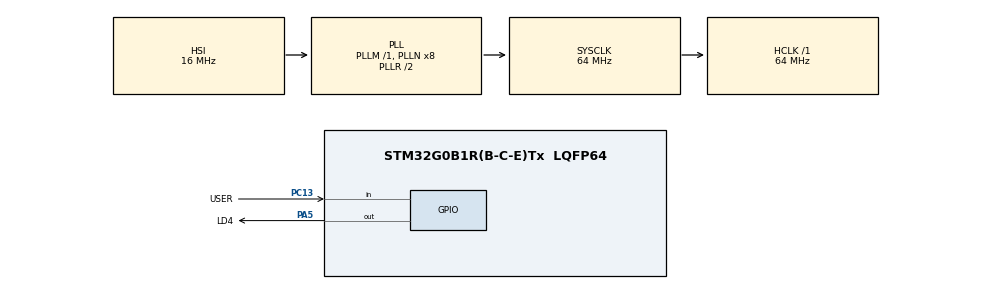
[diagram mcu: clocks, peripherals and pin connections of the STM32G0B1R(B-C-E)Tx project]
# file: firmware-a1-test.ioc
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Mcu.Family=STM32G0
Mcu.Name=STM32G0B1R(B-C-E)Tx
Mcu.Package=LQFP64
PA13.Mode=Serial_Wire
PA13.Signal=SYS_SWDIO
PA14-BOOT0.Mode=Serial_Wire
PA14-BOOT0.Signal=SYS_SWCLK
PA5.GPIO_Label=LD4
PA5.Signal=GPIO_Output
PC13.GPIO_Label=USER
PC13.Signal=GPIO_Input
ProjectManager.HeapSize=0x200
ProjectManager.StackSize=0x400
ProjectManager.TargetToolchain=STM32CubeIDE
RCC.ADCFreq_Value=64000000
RCC.AHBFreq_Value=64000000
RCC.CortexFreq_Value=64000000
RCC.EXTERNAL_CLOCK_VALUE=48000
RCC.HCLKFreq_Value=64000000
RCC.HSE_VALUE=8000000
RCC.HSI48_VALUE=48000000
RCC.HSI_VALUE=16000000
RCC.LSE_VALUE=32768
RCC.SYSCLKFreq_VALUE=64000000
RCC.SYSCLKSource=RCC_SYSCLKSOURCE_PLLCLK
RCC.USBFreq_Value=48000000
RCC.VCOOutputFreq_Value=128000000
VP_SYS_VS_DBSignals.Mode=DisableDeadBatterySignals
board=custom

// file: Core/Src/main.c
/* USER CODE BEGIN Header */
/**
  ******************************************************************************
  * @file           : main.c
  * @brief          : Main program body
  ******************************************************************************
  * @attention
  *
  * Copyright (c) 2022 STMicroelectronics.
  * All rights reserved.
  *
  * This software is licensed under terms that can be found in the LICENSE file
  * in the root directory of this software component.
  * If no LICENSE file comes with this software, it is provided AS-IS.
  *
  ******************************************************************************
  */
/* USER CODE END Header */
#include "main.h"
#include "gpio.h"

/* USER CODE BEGIN PV */
uint32_t i;
/* USER CODE END PV */

void SystemClock_Config(void);

/* USER CODE BEGIN 0 */

/**
 * @brief		Sum a and b
 */
uint8_t sum8(uint8_t a, uint8_t b){
	uint8_t c;

	c = a+b;

	return c;
}

/**
 * @brief		Sum a and b
 */
uint_fast8_t sum8_fast(uint_fast8_t a, uint_fast8_t b){
	uint_fast8_t c;

	c = a+b;

	return c;
}

/* USER CODE END 0 */

int main(void)
{
  /* USER CODE BEGIN 1 */
	uint8_t A = 3, B = 19, C;
	uint_fast8_t Af = 3, Bf = 19, Cf;
  /* USER CODE END 1 */

  /* MCU Configuration--------------------------------------------------------*/

  /* Reset of all peripherals, Initializes the Flash interface and the Systick. */
  HAL_Init();

  /* Configure the system clock */
  SystemClock_Config();

  /* Initialize all configured peripherals */
  MX_GPIO_Init();

  /* Infinite loop */
  /* USER CODE BEGIN WHILE */
  i = 0;
  while (1)
  {
	  if (HAL_GPIO_ReadPin(USER_GPIO_Port, USER_Pin) == GPIO_PIN_RESET){
		  HAL_GPIO_WritePin(LD4_GPIO_Port, LD4_Pin, GPIO_PIN_SET);
	  }
	  else{
		  HAL_GPIO_WritePin(LD4_GPIO_Port, LD4_Pin, GPIO_PIN_RESET);
	  }

	  C = sum8(A, B);
	  Cf = sum8_fast(Af, Bf);

	  i++;
    /* USER CODE END WHILE */

  }
}

void SystemClock_Config(void)
{
  RCC_OscInitTypeDef RCC_OscInitStruct = {0};
  RCC_ClkInitTypeDef RCC_ClkInitStruct = {0};

  /** Configure the main internal regulator output voltage
  */
  HAL_PWREx_ControlVoltageScaling(PWR_REGULATOR_VOLTAGE_SCALE1);
  /** Initializes the RCC Oscillators according to the specified parameters
  * in the RCC_OscInitTypeDef structure.
  */
  RCC_OscInitStruct.OscillatorType = RCC_OSCILLATORTYPE_HSI;
  RCC_OscInitStruct.HSIState = RCC_HSI_ON;
  RCC_OscInitStruct.HSIDiv = RCC_HSI_DIV1;
  RCC_OscInitStruct.HSICalibrationValue = RCC_HSICALIBRATION_DEFAULT;
  RCC_OscInitStruct.PLL.PLLState = RCC_PLL_ON;
  RCC_OscInitStruct.PLL.PLLSource = RCC_PLLSOURCE_HSI;
  RCC_OscInitStruct.PLL.PLLM = RCC_PLLM_DIV1;
  RCC_OscInitStruct.PLL.PLLN = 8;
  RCC_OscInitStruct.PLL.PLLP = RCC_PLLP_DIV2;
  RCC_OscInitStruct.PLL.PLLQ = RCC_PLLQ_DIV2;
  RCC_OscInitStruct.PLL.PLLR = RCC_PLLR_DIV2;
  if (HAL_RCC_OscConfig(&RCC_OscInitStruct) != HAL_OK)
  {
    Error_Handler();
  }
  /** Initializes the CPU, AHB and APB buses clocks
  */
  RCC_ClkInitStruct.ClockType = RCC_CLOCKTYPE_HCLK|RCC_CLOCKTYPE_SYSCLK
                              |RCC_CLOCKTYPE_PCLK1;
  RCC_ClkInitStruct.SYSCLKSource = RCC_SYSCLKSOURCE_PLLCLK;
  RCC_ClkInitStruct.AHBCLKDivider = RCC_SYSCLK_DIV1;
  RCC_ClkInitStruct.APB1CLKDivider = RCC_HCLK_DIV1;

  if (HAL_RCC_ClockConfig(&RCC_ClkInitStruct, FLASH_LATENCY_2) != HAL_OK)
  {
    Error_Handler();
  }
}

void Error_Handler(void)
{
  __disable_irq();
  while (1)
  {
  }
}
